VERSION "0.5.1"

NS_ :

BS_:

BU_: chargeSOM_HostController chargeSOM_SafetyController CCY_HostController CCY_SafetyController

BO_ 255 InquiryPacket: 8 chargeSOM_HostController
 SG_ PacketId : 7|8@0+ (1,0) [0|0] ""  CCY_SafetyController,chargeSOM_SafetyController
 SG_ ActionId : 15|8@0+ (1,0) [0|0] ""  CCY_SafetyController,chargeSOM_SafetyController

BO_ 254 ActionAck: 8 chargeSOM_SafetyController
 SG_ ActionId : 7|8@0+ (1,0) [0|0] ""  CCY_HostController,chargeSOM_HostController

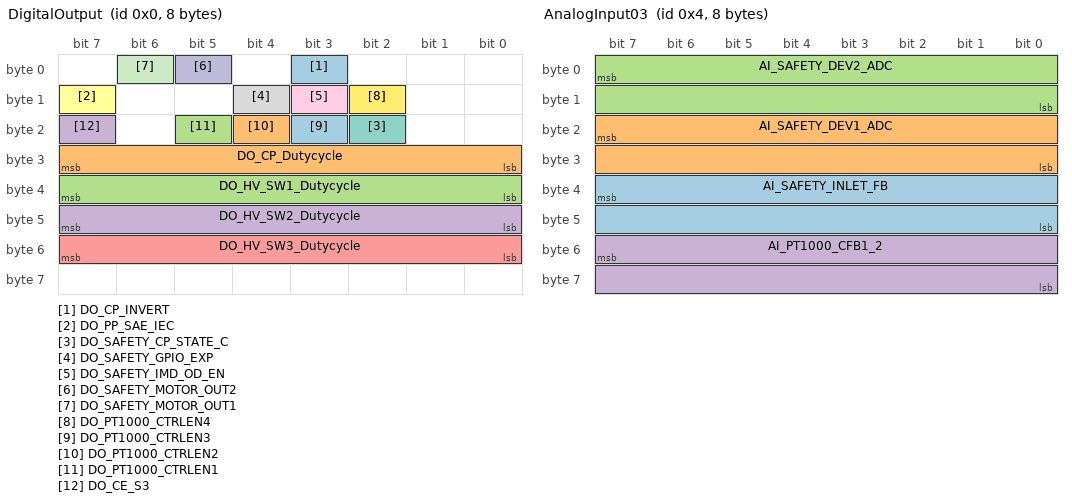
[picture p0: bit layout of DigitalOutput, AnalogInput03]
BO_ 0 DigitalOutput: 8 chargeSOM_HostController
 SG_ DO_CP_INVERT : 3|1@0+ (1,0) [0|0] ""  chargeSOM_SafetyController
 SG_ DO_CP_Dutycycle : 31|8@0+ (1,0) [0|0] "%"  chargeSOM_SafetyController
 SG_ DO_HV_SW1_Dutycycle : 39|8@0+ (1,0) [0|0] "%"  chargeSOM_SafetyController
 SG_ DO_HV_SW2_Dutycycle : 47|8@0+ (1,0) [0|0] "%"  chargeSOM_SafetyController
 SG_ DO_HV_SW3_Dutycycle : 55|8@0+ (1,0) [0|0] "%"  chargeSOM_SafetyController
 SG_ DO_PP_SAE_IEC : 15|1@0+ (1,0) [0|0] ""  chargeSOM_SafetyController
 SG_ DO_SAFETY_CP_STATE_C : 18|1@0+ (1,0) [0|0] ""  chargeSOM_SafetyController,CCY_SafetyController
 SG_ DO_SAFETY_GPIO_EXP : 12|1@0+ (1,0) [0|0] ""  chargeSOM_SafetyController
 SG_ DO_SAFETY_IMD_OD_EN : 11|1@0+ (1,0) [0|0] ""  chargeSOM_SafetyController
 SG_ DO_SAFETY_MOTOR_OUT2 : 5|1@0+ (1,0) [0|0] ""  chargeSOM_SafetyController
 SG_ DO_SAFETY_MOTOR_OUT1 : 6|1@0+ (1,0) [0|0] ""  chargeSOM_SafetyController
 SG_ DO_PT1000_CTRLEN4 : 10|1@0+ (1,0) [0|0] ""  chargeSOM_SafetyController,CCY_SafetyController
 SG_ DO_PT1000_CTRLEN3 : 19|1@0+ (1,0) [0|0] ""  chargeSOM_SafetyController,CCY_SafetyController
 SG_ DO_PT1000_CTRLEN2 : 20|1@0+ (1,0) [0|0] ""  chargeSOM_SafetyController,CCY_SafetyController
 SG_ DO_PT1000_CTRLEN1 : 21|1@0+ (1,0) [0|0] ""  chargeSOM_SafetyController,CCY_SafetyController
 SG_ DO_CE_S3 : 23|1@0+ (1,0) [0|0] ""  CCY_SafetyController

BO_ 18 DiagnosticMeasurements2: 8 CCY_SafetyController
 SG_ DM_ID_ADC_VAL : 23|16@0+ (1,0) [0|0] ""  CCY_HostController
 SG_ DM_CE_ADC_VAL : 7|16@0+ (1,0) [0|0] ""  CCY_HostController

BO_ 5 AnalogInput04: 8 chargeSOM_SafetyController
 SG_ AI_PT1000_CFB3_4 : 7|16@0+ (1,0) [0|0] ""  CCY_HostController,chargeSOM_HostController

BO_ 4 AnalogInput03: 8 chargeSOM_SafetyController
 SG_ AI_SAFETY_INLET_FB : 39|16@0+ (1,0) [0|0] ""  CCY_HostController,chargeSOM_HostController
 SG_ AI_SAFETY_DEV1_ADC : 23|16@0+ (1,0) [0|0] ""  CCY_HostController,chargeSOM_HostController
 SG_ AI_SAFETY_DEV2_ADC : 7|16@0+ (1,0) [0|0] ""  CCY_HostController,chargeSOM_HostController
 SG_ AI_PT1000_CFB1_2 : 55|16@0+ (1,0) [0|0] ""  CCY_HostController,chargeSOM_HostController

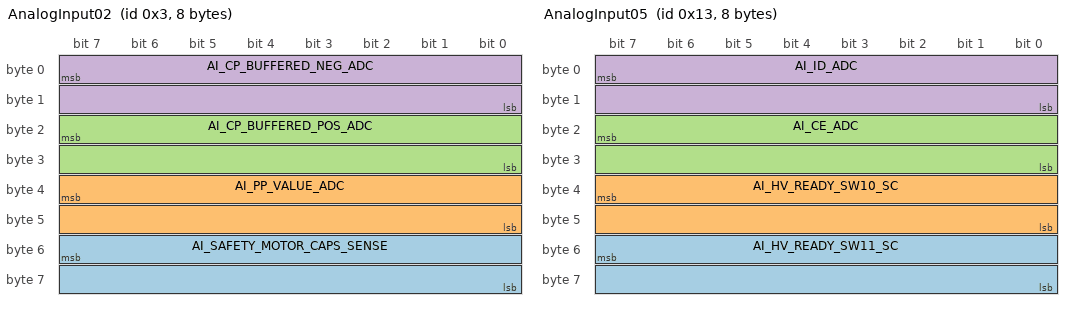
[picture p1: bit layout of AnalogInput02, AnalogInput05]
BO_ 3 AnalogInput02: 8 chargeSOM_SafetyController
 SG_ AI_SAFETY_MOTOR_CAPS_SENSE : 55|16@0+ (1,0) [0|0] ""  chargeSOM_HostController
 SG_ AI_PP_VALUE_ADC : 39|16@0+ (1,0) [0|0] ""  chargeSOM_HostController
 SG_ AI_CP_BUFFERED_POS_ADC : 23|16@0+ (1,0) [0|0] ""  chargeSOM_HostController
 SG_ AI_CP_BUFFERED_NEG_ADC : 7|16@0+ (1,0) [0|0] ""  chargeSOM_HostController

BO_ 19 AnalogInput05: 8 CCY_SafetyController
 SG_ AI_HV_READY_SW11_SC : 55|16@0+ (1,0) [0|0] ""  CCY_HostController
 SG_ AI_HV_READY_SW10_SC : 39|16@0+ (1,0) [0|0] ""  CCY_HostController
 SG_ AI_CE_ADC : 23|16@0+ (1,0) [0|0] ""  CCY_HostController
 SG_ AI_ID_ADC : 7|16@0+ (1,0) [0|0] ""  CCY_HostController

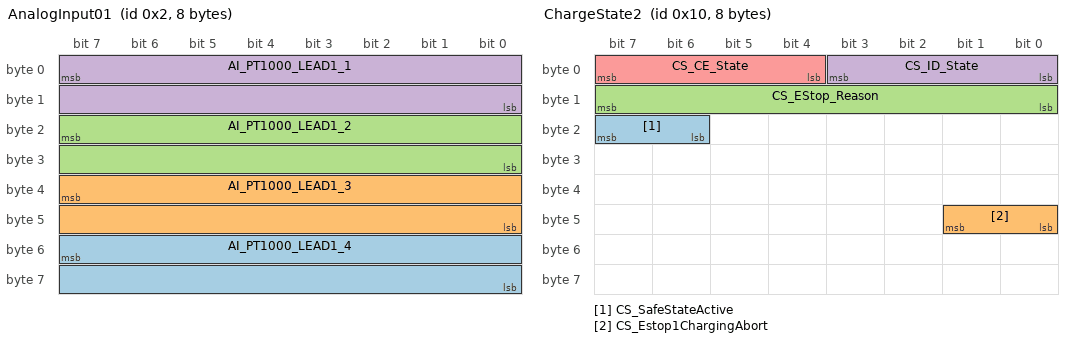
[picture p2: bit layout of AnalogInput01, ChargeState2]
BO_ 2 AnalogInput01: 8 chargeSOM_SafetyController
 SG_ AI_PT1000_LEAD1_4 : 55|16@0+ (1,0) [0|0] ""  CCY_HostController,chargeSOM_HostController
 SG_ AI_PT1000_LEAD1_3 : 39|16@0+ (1,0) [0|0] ""  CCY_HostController,chargeSOM_HostController
 SG_ AI_PT1000_LEAD1_2 : 23|16@0+ (1,0) [0|0] ""  CCY_HostController,chargeSOM_HostController
 SG_ AI_PT1000_LEAD1_1 : 7|16@0+ (1,0) [0|0] ""  CCY_HostController,chargeSOM_HostController

BO_ 17 ChargeControl2: 8 CCY_HostController
 SG_ CC_ControllerReset : 3|2@0+ (1,0) [0|0] ""  CCY_SafetyController
 SG_ CC_CCSReady : 7|4@0+ (1,0) [0|0] ""  CCY_SafetyController

BO_ 16 ChargeState2: 8 CCY_SafetyController
 SG_ CS_SafeStateActive : 23|2@0+ (1,0) [0|0] ""  CCY_HostController
 SG_ CS_Estop1ChargingAbort : 41|2@0+ (1,0) [0|0] ""  CCY_HostController
 SG_ CS_EStop_Reason : 15|8@0+ (1,0) [0|0] ""  CCY_HostController
 SG_ CS_ID_State : 3|4@0+ (1,0) [0|0] ""  CCY_HostController
 SG_ CS_CE_State : 7|4@0+ (1,0) [0|0] ""  CCY_HostController

BO_ 7 ChargeState1: 8 chargeSOM_SafetyController
 SG_ CS_SafeStateReason : 55|8@0+ (1,0) [0|0] ""  chargeSOM_HostController
 SG_ CS_SafeStateActive : 3|2@0+ (1,0) [0|0] ""  chargeSOM_HostController
 SG_ CS_Estop1ChargingAbort : 41|2@0+ (1,0) [0|0] ""  chargeSOM_HostController
 SG_ CS_Estop2ChargingAbort : 43|2@0+ (1,0) [0|0] ""  chargeSOM_HostController
 SG_ CS_Estop3ChargingAbort : 45|2@0+ (1,0) [0|0] ""  chargeSOM_HostController
 SG_ CS_RcmStatus : 47|2@0+ (1,0) [0|0] ""  chargeSOM_HostController
 SG_ CS_Estop4IMDChargingAbort : 57|2@0+ (1,0) [0|0] ""  chargeSOM_HostController
 SG_ CS_InletState : 23|3@0+ (1,0) [0|0] ""  chargeSOM_HostController
 SG_ CS_Contactor1State : 33|2@0+ (1,0) [0|0] ""  chargeSOM_HostController
 SG_ CS_Contactor2State : 35|2@0+ (1,0) [0|0] ""  chargeSOM_HostController
 SG_ CS_Contactor3State : 37|2@0+ (1,0) [0|0] ""  chargeSOM_HostController
 SG_ CS_HV_Ready : 38|1@0+ (1,0) [0|0] ""  chargeSOM_HostController
 SG_ CS_CurrentPpState : 26|3@0+ (1,0) [0|0] ""  chargeSOM_HostController
 SG_ CS_CurrentCpState : 18|3@0+ (1,0) [0|0] ""  chargeSOM_HostController
 SG_ CS_CpShortCircuit : 19|1@0+ (1,0) [0|0] ""  chargeSOM_HostController
 SG_ CS_DiodeFault : 20|1@0+ (1,0) [0|0] ""  chargeSOM_HostController
 SG_ CS_CurrentDutyCycle : 1|10@0+ (0.1,0) [0|0] "%"  chargeSOM_HostController
 SG_ CS_PWM_Active : 7|1@0+ (1,0) [0|0] ""  chargeSOM_HostController

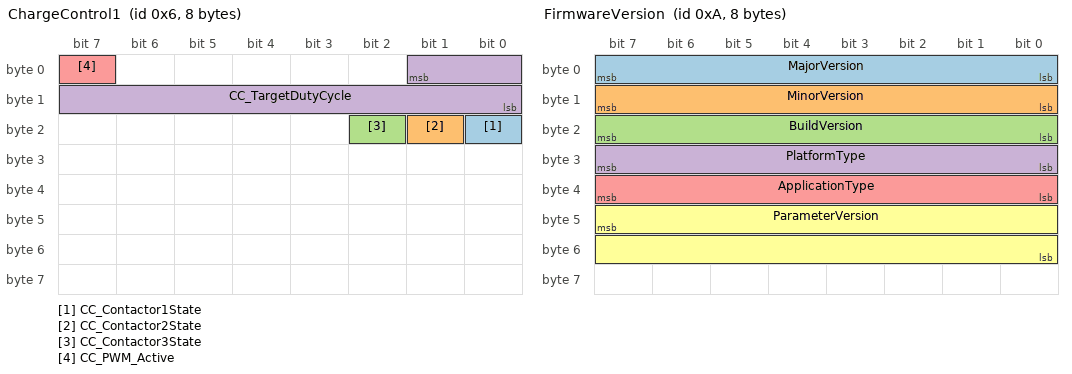
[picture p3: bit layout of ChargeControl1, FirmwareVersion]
BO_ 6 ChargeControl1: 8 chargeSOM_HostController
 SG_ CC_Contactor1State : 16|1@0+ (1,0) [0|0] ""  chargeSOM_SafetyController
 SG_ CC_Contactor2State : 17|1@0+ (1,0) [0|0] ""  chargeSOM_SafetyController
 SG_ CC_Contactor3State : 18|1@0+ (1,0) [0|0] ""  chargeSOM_SafetyController
 SG_ CC_TargetDutyCycle : 1|10@0+ (0.1,0) [0|0] "%"  chargeSOM_SafetyController
 SG_ CC_PWM_Active : 7|1@0+ (1,0) [0|0] ""  chargeSOM_SafetyController

BO_ 10 FirmwareVersion: 8 chargeSOM_SafetyController
 SG_ MajorVersion : 7|8@0+ (1,0) [0|0] ""  chargeSOM_HostController,CCY_HostController
 SG_ MinorVersion : 15|8@0+ (1,0) [0|0] ""  chargeSOM_HostController,CCY_HostController
 SG_ BuildVersion : 23|8@0+ (1,0) [0|0] ""  chargeSOM_HostController,CCY_HostController
 SG_ PlatformType : 31|8@0+ (1,0) [0|0] ""  chargeSOM_HostController,CCY_HostController
 SG_ ApplicationType : 39|8@0+ (1,0) [0|0] ""  chargeSOM_HostController,CCY_HostController
 SG_ ParameterVersion : 47|16@0+ (1,0) [0|0] ""  chargeSOM_HostController,CCY_HostController

BO_ 11 GitHash: 8 chargeSOM_SafetyController
 SG_ HashSignal : 7|64@0+ (1,0) [0|0] ""  chargeSOM_HostController,CCY_HostController

BO_ 20 PartNumber1: 8 chargeSOM_SafetyController
 SG_ PartNumber1Signal : 7|64@0+ (1,0) [0|0] ""  chargeSOM_HostController,CCY_HostController

BO_ 21 PartNumber2: 8 chargeSOM_SafetyController
 SG_ PartNumber2Signal : 7|64@0+ (1,0) [0|0] ""  chargeSOM_HostController,CCY_HostController

BO_ 22 ChipInfo: 8 chargeSOM_SafetyController
 SG_ MCUVersion : 7|8@0+ (1,0) [0|0] ""  chargeSOM_HostController,CCY_HostController

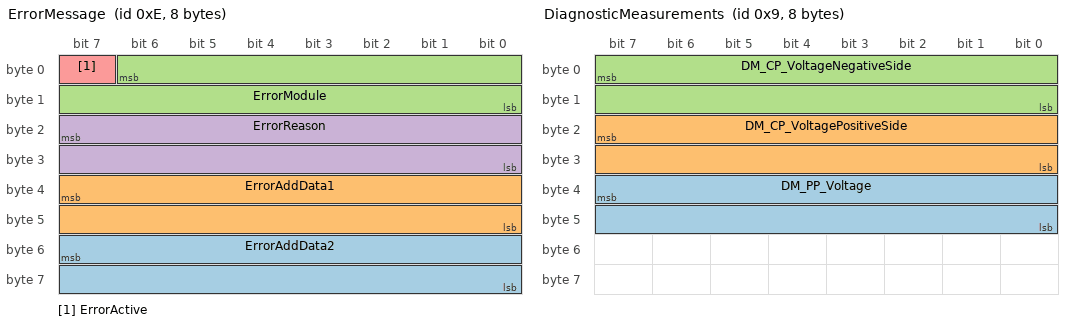
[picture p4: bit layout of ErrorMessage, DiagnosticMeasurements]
BO_ 14 ErrorMessage: 8 chargeSOM_SafetyController
 SG_ ErrorAddData2 : 55|16@0+ (1,0) [0|0] ""  chargeSOM_HostController,CCY_HostController
 SG_ ErrorAddData1 : 39|16@0+ (1,0) [0|0] ""  chargeSOM_HostController,CCY_HostController
 SG_ ErrorModule : 6|15@0+ (1,0) [0|0] ""  chargeSOM_HostController,CCY_HostController
 SG_ ErrorReason : 23|16@0+ (1,0) [0|0] ""  chargeSOM_HostController,CCY_HostController
 SG_ ErrorActive : 7|1@0+ (1,0) [0|0] ""  chargeSOM_HostController,CCY_HostController

BO_ 9 DiagnosticMeasurements: 8 chargeSOM_SafetyController
 SG_ DM_PP_Voltage : 39|16@0- (1,0) [0|0] ""  chargeSOM_SafetyController,chargeSOM_HostController
 SG_ DM_CP_VoltagePositiveSide : 23|16@0- (1,0) [0|0] ""  chargeSOM_SafetyController,chargeSOM_HostController
 SG_ DM_CP_VoltageNegativeSide : 7|16@0- (1,0) [0|0] ""  chargeSOM_SafetyController,chargeSOM_HostController

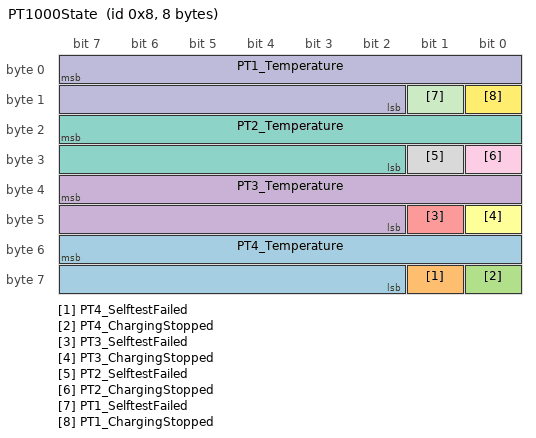
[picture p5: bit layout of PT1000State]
BO_ 8 PT1000State: 8 chargeSOM_SafetyController
 SG_ PT4_Temperature : 55|14@0- (0.1,0) [0|0] "°C"  chargeSOM_HostController,CCY_HostController
 SG_ PT4_SelftestFailed : 57|1@0+ (1,0) [0|0] ""  chargeSOM_HostController,CCY_HostController
 SG_ PT4_ChargingStopped : 56|1@0+ (1,0) [0|0] ""  chargeSOM_HostController,CCY_HostController
 SG_ PT3_Temperature : 39|14@0- (0.1,0) [0|0] "°C"  chargeSOM_HostController,CCY_HostController
 SG_ PT3_SelftestFailed : 41|1@0+ (1,0) [0|0] ""  chargeSOM_HostController,CCY_HostController
 SG_ PT3_ChargingStopped : 40|1@0+ (1,0) [0|0] ""  chargeSOM_HostController,CCY_HostController
 SG_ PT2_Temperature : 23|14@0- (0.1,0) [0|0] "°C"  chargeSOM_HostController,CCY_HostController
 SG_ PT2_SelftestFailed : 25|1@0+ (1,0) [0|0] ""  chargeSOM_HostController,CCY_HostController
 SG_ PT2_ChargingStopped : 24|1@0+ (1,0) [0|0] ""  chargeSOM_HostController,CCY_HostController
 SG_ PT1_Temperature : 7|14@0- (0.1,0) [0|0] "°C"  chargeSOM_HostController,CCY_HostController
 SG_ PT1_SelftestFailed : 9|1@0+ (1,0) [0|0] ""  chargeSOM_HostController,CCY_HostController
 SG_ PT1_ChargingStopped : 8|1@0+ (1,0) [0|0] ""  chargeSOM_HostController,CCY_HostController

BO_ 1 DigitalInput: 8 CCY_SafetyController
 SG_ DI_SAFETY_CP_STATE_C : 19|1@0+ (1,0) [0|0] ""  chargeSOM_HostController,CCY_HostController
 SG_ DI_SAFETY_MOTOR_OUT1 : 6|1@0+ (1,0) [0|0] ""  chargeSOM_HostController
 SG_ DI_SAFETY_MOTOR_OUT2 : 5|1@0+ (1,0) [0|0] ""  chargeSOM_HostController
 SG_ DI_SAFETY_MOTOR_FAULT : 4|1@0+ (1,0) [0|0] ""  chargeSOM_HostController
 SG_ DI_PP_SAE_IEC : 15|1@0+ (1,0) [0|0] ""  chargeSOM_HostController
 SG_ DI_EV_CP_EDGE : 2|1@0+ (1,0) [0|0] ""  chargeSOM_HostController
 SG_ DI_CP_INVERT : 3|1@0+ (1,0) [0|0] ""  chargeSOM_HostController
 SG_ DI_SAFETY_K1_IN : 7|1@0+ (1,0) [0|0] ""  chargeSOM_HostController
 SG_ DI_PT4_EN : 10|1@0+ (1,0) [0|0] ""  chargeSOM_HostController,CCY_HostController
 SG_ DI_PT3_EN : 20|1@0+ (1,0) [0|0] ""  chargeSOM_HostController,CCY_HostController
 SG_ DI_PT2_EN : 21|1@0+ (1,0) [0|0] ""  chargeSOM_HostController,CCY_HostController
 SG_ DI_PT1_EN : 22|1@0+ (1,0) [0|0] ""  chargeSOM_HostController,CCY_HostController
 SG_ DI_SAFETY_IMD_OD_EN : 11|1@0+ (1,0) [0|0] ""  chargeSOM_HostController
 SG_ DI_SAFETY_GPIO_EXP : 12|1@0+ (1,0) [0|0] ""  chargeSOM_HostController
 SG_ DI_ESTOP3 : 16|1@0+ (1,0) [0|0] ""  chargeSOM_HostController
 SG_ DI_ESTOP2 : 17|1@0+ (1,0) [0|0] ""  chargeSOM_HostController
 SG_ DI_ESTOP1 : 18|1@0+ (1,0) [0|0] ""  chargeSOM_HostController,CCY_HostController
 SG_ DI_SAFETY_K2_IN : 8|1@0+ (1,0) [0|0] ""  chargeSOM_HostController
 SG_ DI_CE_S3 : 23|1@0+ (1,0) [0|0] ""  CCY_HostController

BO_TX_BU_ 255 : CCY_HostController,chargeSOM_HostController;
BO_TX_BU_ 5 : CCY_SafetyController,chargeSOM_SafetyController;
BO_TX_BU_ 4 : CCY_SafetyController,chargeSOM_SafetyController;
BO_TX_BU_ 2 : CCY_SafetyController,chargeSOM_SafetyController;
BO_TX_BU_ 10 : CCY_SafetyController,chargeSOM_SafetyController;
BO_TX_BU_ 11 : CCY_SafetyController,chargeSOM_SafetyController;
BO_TX_BU_ 20 : CCY_SafetyController,chargeSOM_SafetyController;
BO_TX_BU_ 21 : CCY_SafetyController,chargeSOM_SafetyController;
BO_TX_BU_ 22 : CCY_SafetyController,chargeSOM_SafetyController;
BO_TX_BU_ 14 : CCY_SafetyController,chargeSOM_SafetyController;
BO_TX_BU_ 8 : CCY_SafetyController,chargeSOM_SafetyController;
BO_TX_BU_ 1 : chargeSOM_SafetyController,CCY_SafetyController;

CM_ BO_ 255 "This packet is used to request a special message from the safety controller";
CM_ SG_ 255 PacketId "The ID, which message shall be requested. Supported values are described below.";
CM_ SG_ 16 CS_SafeStateActive "This signal reports, if the controller is in safeState or not.";
CM_ BO_ 7 "This message shall be sent from safety controller to host processor for indicating the state of the charging session as well as the state of connected peripherals.";
CM_ SG_ 7 CS_SafeStateReason "This signal describes in which module a fault was detected, why the controller went into safeState";
CM_ SG_ 7 CS_SafeStateActive "This signal reports, if the controller is in safeState or not.";
CM_ SG_ 7 CS_Contactor1State "State of contactor 1";
CM_ SG_ 7 CS_Contactor2State "State of contactor 2";
CM_ SG_ 7 CS_Contactor3State "State of contactor 3";
CM_ SG_ 7 CS_HV_Ready "This is the state of the HV ready or State C output. This output is high, if the chargeSOM dont see any errors and CP is at state C. Otherwise it is low.";
CM_ SG_ 7 CS_CurrentPpState "State of the proximity pin. For fixed cables at CCS2, this value is 0x0: No Cable detected";
CM_ SG_ 7 CS_CurrentCpState "Current state of the control pilot. See value mappings below";
CM_ SG_ 7 CS_CpShortCircuit " Is set when the safety controller detects a short-circuit condition between CP and PE line.";
CM_ SG_ 7 CS_DiodeFault " Is set when the safety controller detects that the diode on EV side is missing.";
CM_ SG_ 7 CS_CurrentDutyCycle "The current duty cycle between 0.0% and 100.0%. If the PWM is not aczive this signal is 0";
CM_ SG_ 7 CS_PWM_Active "Feedback if PWM is active. 0 means not active, 1 means active";
CM_ BO_ 6 "This message shall be sent from the host processor to the safety controller to control the peripherals connected to the safety controller.";
CM_ SG_ 6 CC_Contactor1State "Request to close the contactor state. A value of 0 means open contactor, a value of 1 means closed contactor. The contactors are only closed if the system has no errors and is in state C.";
CM_ SG_ 6 CC_Contactor2State "Request to close the contactor state. A value of 0 means open contactor, a value of 1 means closed contactor. The contactors are only closed if the system has no errors and is in state C.";
CM_ SG_ 6 CC_Contactor3State "Request to close the contactor state. A value of 0 means open contactor, a value of 1 means closed contactor. The contactors are only closed if the system has no errors and is in state C.";
CM_ SG_ 6 CC_TargetDutyCycle "Duty cycle between 0.0 and 100.0%. Values above 100.0% are set as 100%. Only valid if the signal CC_PWM_Active is 1";
CM_ SG_ 6 CC_PWM_Active "This flag indicates if the PWM should be activated. At a value of 0, the CP level is also 0V. At a value of 1, the CP level is dependant of the duty cycle";
CM_ BO_ 10 "This message provides information about the type and version of the flashed firmware";
CM_ SG_ 10 MajorVersion "Major version of the firmware";
CM_ SG_ 10 MinorVersion "Minor version of the firmware";
CM_ SG_ 10 BuildVersion "Build or patch version of the firmware";
CM_ SG_ 10 PlatformType "This firmware can be used for several products with minor changes in the build process. The platform type describes the used platform";
CM_ SG_ 10 ApplicationType "The type of firmware. See possible values below";
CM_ SG_ 10 ParameterVersion "Version of the parameter file";
CM_ BO_ 11 "This message provides information about the GIT hash, written in the firmware";
CM_ SG_ 11 HashSignal "First 8 byte of the 160 bit (SHA-1) GIT hash";
CM_ BO_ 8 "This message shall be sent from safety controller to host processor for indicating the state of the connected temperature sensors";
CM_ SG_ 8 PT4_Temperature "Current temperature of PT1000 channel in °C with one decimal digit. 0x1FFF stands for: temp sensor not used.";
CM_ SG_ 8 PT4_SelftestFailed "Indicates whether this PT1000 channel is disturbed, multiple channel can signal the condition in parallel.";
CM_ SG_ 8 PT4_ChargingStopped "Indicates whether this PT1000 channel prevents charging, multiple channel can signal the condition in parallel.";
CM_ SG_ 8 PT3_Temperature "Current temperature of PT1000 channel in °C with one decimal digit. 0x1FFF stands for: temp sensor not used.";
CM_ SG_ 8 PT3_SelftestFailed "Indicates whether this PT1000 channel is disturbed, multiple channel can signal the condition in parallel.";
CM_ SG_ 8 PT3_ChargingStopped "Indicates whether this PT1000 channel prevents charging, multiple channel can signal the condition in parallel.";
CM_ SG_ 8 PT2_Temperature "Current temperature of PT1000 channel in °C with one decimal digit. 0x1FFF stands for: temp sensor not used.";
CM_ SG_ 8 PT2_SelftestFailed "Indicates whether this PT1000 channel is disturbed, multiple channel can signal the condition in parallel.";
CM_ SG_ 8 PT2_ChargingStopped "Indicates whether this PT1000 channel prevents charging, multiple channel can signal the condition in parallel.";
CM_ SG_ 8 PT1_Temperature "Current temperature of PT1000 channel in °C with one decimal digit. 0x1FFF stands for: temp sensor not used.";
CM_ SG_ 8 PT1_SelftestFailed "Indicates whether this PT1000 channel is disturbed, multiple channel can signal the condition in parallel.";
CM_ SG_ 8 PT1_ChargingStopped "Indicates whether this PT1000 channel prevents charging, multiple channel can signal the condition in parallel.";
BA_DEF_  "BusType" STRING ;
BA_DEF_DEF_  "BusType" "";
BA_ "BusType" "J1708";
VAL_ 255 PacketId 10 "FirmwareVersion" 11 "GitHash" 20 "PartNumber1" 21 "PartNumber2" 22 "ChipInfo" ;
VAL_ 255 ActionId 0 "No Action requested" 1 "Start RCM Selftest" 2 "Request Inlet Closing" 3 "Request Inlet Opening";
VAL_ 17 CC_CCSReady 2 "CCS_EmergencyStop" 1 "CCS_Ready" 0 "CCS_NotReady" ;
VAL_ 16 CS_SafeStateActive 3 "SNA" 1 "SafeState" 0 "NormalState" ;
VAL_ 16 CS_Estop1ChargingAbort 0 "FALSE" 1 "TRUE" 3 "NotConfigured" ;
VAL_ 16 CS_EStop_Reason 22 "ParameterFailure" 16 "EmergencyInput" 13 "HVReady_Malfunction" 12 "CE_Malfunction" 11 "ID_Malfunction" 10 "Temp4_Overtemp" 9 "Temp3_Overtemp" 8 "Temp2_Overtemp" 7 "Temp1_Overtemp" 6 "Temp4_Malfunction" 5 "Temp3_Malfunction" 4 "Temp2_Malfunction" 3 "Temp1_Malfunction" 2 "ComTimeout" 1 "InternalError" 0 "NoStop" ;
VAL_ 16 CS_ID_State 3 "Invalid" 2 "Connected" 1 "Not Connected" 0 "Unknown" ;
VAL_ 16 CS_CE_State 7 "Invalid" 6 "EC" 5 "E" 4 "C" 3 "B" 2 "B0" 1 "A" 0 "Unknown" ;
VAL_ 7 CS_SafeStateReason 22 "ParameterFailure" 21 "RCM_SelftestFailed" 20 "RCM_Error" 19 "EmergencyInput4IMD" 18 "EmergencyInput3" 17 "EmergencyInput2" 16 "EmergencyInput1" 15 "HVSW_Malfunction" 14 "CP_DiodeFault" 13 "CP_ShortCircuit" 12 "CP_Malfunction" 11 "PP_Malfunction" 10 "Temp4_Overtemp" 9 "Temp3_Overtemp" 8 "Temp2_Overtemp" 7 "Temp1_Overtemp" 6 "Temp4_Malfunction" 5 "Temp3_Malfunction" 4 "Temp2_Malfunction" 3 "Temp1_Malfunction" 2 "ComTimeout" 1 "InternalError" 0 "NoStop" ;
VAL_ 7 CS_SafeStateActive 3 "SNA" 1 "SafeState" 0 "NormalState" ;
VAL_ 7 CS_Estop1ChargingAbort 0 "FALSE" 1 "TRUE" 3 "NotConfigured" ;
VAL_ 7 CS_Estop2ChargingAbort 0 "FALSE" 1 "TRUE" 3 "NotConfigured" ;
VAL_ 7 CS_Estop3ChargingAbort 0 "FALSE" 1 "TRUE" 3 "NotConfigured" ;
VAL_ 7 CS_Estop4IMDChargingAbort 0 "FALSE" 1 "TRUE" 3 "NotConfigured" ;
VAL_ 7 CS_RcmStatus 0 "NotConfigured" 1 "MONITORING" 2 "SELFTEST" 3 "ERROR" ;
VAL_ 7 CS_InletState 0 "UNDEFINED" 1 "OPEN" 2 "OPENING" 3 "CLOSED" 4 "CLOSING" 5 "ERROR" 7 "NotConfigured" ;
VAL_ 7 CS_Contactor1State 0 "UNDEFINED" 1 "OPEN" 2 "CLOSE" 3 "NotConfigured" ;
VAL_ 7 CS_Contactor2State 0 "UNDEFINED" 1 "OPEN" 2 "CLOSE" 3 "NotConfigured" ;
VAL_ 7 CS_Contactor3State 0 "UNDEFINED" 1 "OPEN" 2 "CLOSE" 3 "NotConfigured" ;
VAL_ 7 CS_CurrentPpState 7 "Error" 6 "Type1_ConnectedButtonPressed" 5 "Type1_Connected" 4 "63/70A" 3 "32A" 2 "20A" 1 "13A" 0 "NoCableDetected" ;
VAL_ 7 CS_CurrentCpState 0 "Unknown" 7 "Invalid" 6 "F" 5 "E" 4 "D" 3 "C" 2 "B" 1 "A" ;
VAL_ 10 PlatformType 129 "chargeSOM" 130 "CCY" ;
VAL_ 10 ApplicationType 3 "Firmware" 4 "End Of Line" 5 "Qualification" ;
VAL_ 8 PT4_Temperature 8191 "TempSensorNotUsed" ;
VAL_ 8 PT3_Temperature 8191 "TempSensorNotUsed" ;
VAL_ 8 PT2_Temperature 8191 "TempSensorNotUsed" ;
VAL_ 8 PT1_Temperature 8191 "TempSensorNotUsed" ;
